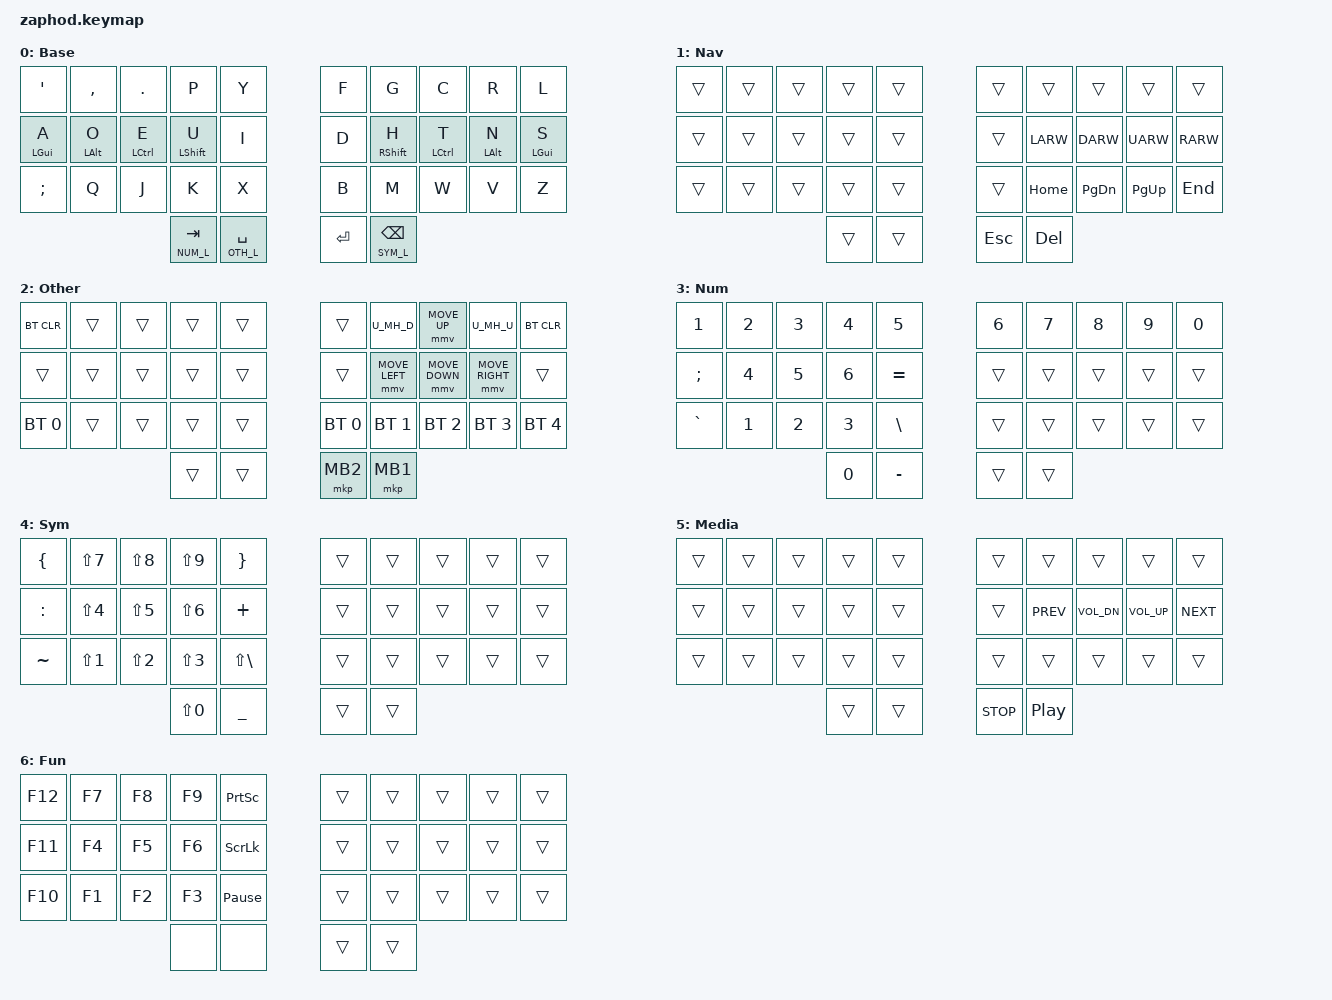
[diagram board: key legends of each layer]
/*
 * Copyright (c) 2021 Pete Johanson
 *
 * SPDX-License-Identifier: MIT
 */

#include <behaviors.dtsi>
#include <dt-bindings/zmk/keys.h>
#include <dt-bindings/zmk/bt.h>
#include <dt-bindings/zmk/outputs.h>
#include <dt-bindings/zmk/mouse.h>

&mmv {
  acceleration-exponent = <1>;      // 1
  time-to-max-speed-ms = <1500>;    // 40
  delay-ms = <0>;                   // 0
};

&mwh {
  acceleration-exponent = <1>;      // 0
  time-to-max-speed-ms = <5000>;    // 40
  delay-ms = <0>;                   // 10
};

#define U_MOUSE_MOVE_MAX 1250       // 600
#define U_MOUSE_SCROLL_MAX 100      // 10

#undef MOVE_UP
#undef MOVE_DOWN
#undef MOVE_LEFT
#undef MOVE_RIGHT
#define MOVE_UP MOVE_VERT(-U_MOUSE_MOVE_MAX)
#define MOVE_DOWN MOVE_VERT(U_MOUSE_MOVE_MAX)
#define MOVE_LEFT MOVE_HOR(-U_MOUSE_MOVE_MAX)
#define MOVE_RIGHT MOVE_HOR(U_MOUSE_MOVE_MAX)

#undef SCROLL_UP
#undef SCROLL_DOWN
#undef SCROLL_LEFT
#undef SCROLL_RIGHT
#define SCROLL_UP SCROLL_VERT(U_MOUSE_SCROLL_MAX)
#define SCROLL_DOWN SCROLL_VERT(-U_MOUSE_SCROLL_MAX)
#define SCROLL_LEFT SCROLL_HOR(-U_MOUSE_SCROLL_MAX)
#define SCROLL_RIGHT SCROLL_HOR(U_MOUSE_SCROLL_MAX)

#define U_BTN1 &mkp MB1
#define U_BTN2 &mkp MB2
#define U_BTN3 &mkp MB3
#define U_MS_U &mmv MOVE_UP
#define U_MS_D &mmv MOVE_DOWN
#define U_MS_L &mmv MOVE_LEFT
#define U_MS_R &mmv MOVE_RIGHT
#define U_WH_U &mwh SCROLL_UP
#define U_WH_D &mwh SCROLL_DOWN
#define U_WH_L &mwh SCROLL_LEFT
#define U_WH_R &mwh SCROLL_RIGHT

#define NAV_L 1
#define OTH_L 2
#define NUM_L 3
#define SYM_L 4
#define MED_L 5
#define FUN_L 6

// Using layer taps on thumbs, having quick tap as well helps w/ repeating space/backspace
&lt { quick_tap_ms = <150>; };

/ {
    combos {
        compatible = "zmk,combos";

        med_mo {
	    timeout-ms = <50>;
            key-positions = <30 31>;
            bindings = <&mo MED_L>;
        };

        fn_mo {
	    timeout-ms = <50>;
            key-positions = <32 33>;
            bindings = <&mo FUN_L>;
        };

    };

    behaviors {
        hm: homerow_mods {
            compatible = "zmk,behavior-hold-tap";
            label = "homerow mods";
            #binding-cells = <2>;
            tapping_term_ms = <200>;
            flavor = "tap-preferred";
            quick-tap-ms = <125>;
            global-quick-tap;
            bindings = <&kp>, <&kp>;
        };
    };

    keymap {
        compatible = "zmk,keymap";

        default_layer {
            label = "Base";
            bindings = <
                &kp SQT      &kp COMMA      &kp DOT       &kp P          &kp Y         &kp F            &kp G          &kp C       &kp R      &kp L
                &hm LGUI A &hm LALT O &hm LCTRL E &hm LSHFT U    &kp I         &kp D            &hm RSHFT H    &hm LCTRL T &hm LALT N &hm LGUI S
                &kp SEMI      &kp Q      &kp J       &kp K          &kp X         &kp B            &kp M          &kp W   &kp V    &kp Z
                                                  &lt NUM_L TAB  &lt OTH_L SPACE &kp RET  &lt SYM_L BKSP
            >;
        };

        nav_layer {
            label = "Nav";
            bindings = <
                &trans     &trans     &trans      &trans          &trans       &trans           &trans         &trans      &trans     &trans
                &trans     &trans     &trans      &trans          &trans       &trans           &kp LARW       &kp DARW    &kp UARW   &kp RARW
                &trans     &trans     &trans      &trans          &trans       &trans           &kp HOME       &kp PG_DN   &kp PG_UP  &kp END
                                                  &trans          &trans       &kp ESC          &kp DEL
            >;
        };

        other_layer {
            label = "Other";
            bindings = <
                &bt BT_CLR	   &trans     &trans      &trans          &trans             &trans           U_MH_D         U_MS_U       U_MH_U       &bt BT_CLR
                &trans     &trans     &trans      &trans          &trans             &trans           U_MS_L         U_MS_D       U_MS_R       &trans
                &bt BT_SEL 0     &trans     &trans      &trans    &trans             &bt BT_SEL 0     &bt BT_SEL 1   &bt BT_SEL 2 &bt BT_SEL 3 &bt BT_SEL 4
                                                  &trans          &trans             U_BTN2           U_BTN1
            >;
        };

        num_layer {
            label = "Num";
            bindings = <
                &kp N1   &kp N2     &kp N3      &kp N4            &kp N5          &kp N6         &kp N7      &kp N8     &kp N9 &kp N0
                &kp SEMI   &kp N4     &kp N5      &kp N6          &kp EQUAL     &trans          &trans         &trans      &trans     &trans
                &kp GRAVE  &kp N1     &kp N2      &kp N3          &kp BSLH      &trans          &trans         &trans      &trans     &trans
                                                  &kp N0          &kp MINUS     &trans          &trans
            >;
        };

        sym_layer {
            label = "Sym";
            bindings = <
                &kp LBRC     &kp LS(N7)  &kp LS(N8)  &kp LS(N9) &kp RBRC        &trans &trans   &trans    &trans    &trans
                &kp COLON    &kp LS(N4)  &kp LS(N5)  &kp LS(N6) &kp PLUS        &trans &trans   &trans    &trans    &trans
                &kp TILDE    &kp LS(N1)  &kp LS(N2)  &kp LS(N3) &kp LS(BSLH)    &trans &trans   &trans    &trans    &trans
                                                   &kp LS(N0) &kp UNDER         &trans &trans
            >;
        };

        media_layer {
            label = "Media";
            bindings = <
                &trans	   &trans     &trans      &trans          &trans       &trans           &trans         &trans       &trans       &trans
                &trans     &trans     &trans      &trans          &trans       &trans           &kp C_PREV     &kp C_VOL_DN &kp C_VOL_UP &kp C_NEXT
                &trans     &trans     &trans      &trans          &trans       &trans           &trans         &trans       &trans       &trans
                                                  &trans          &trans       &kp C_STOP       &kp C_PLAY_PAUSE
            >;
        };

        fun_layer {
            label = "Fun";
            bindings = <
                &kp F12     &kp F7     &kp F8      &kp F9     &kp PSCRN         &trans          &trans         &trans      &trans     &trans
                &kp F11     &kp F4     &kp F5      &kp F6     &kp SLCK          &trans          &trans         &trans      &trans     &trans
                &kp F10     &kp F1     &kp F2      &kp F3     &kp PAUSE_BREAK   &trans          &trans         &trans      &trans     &trans
                                                   &none      &none             &trans          &trans
            >;
        };
    };
};

